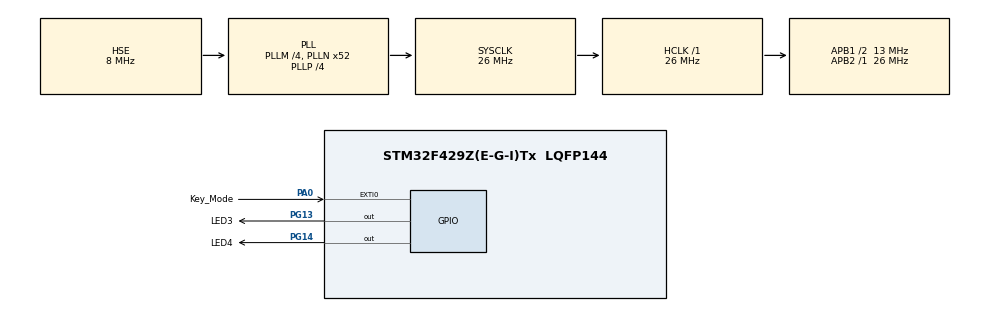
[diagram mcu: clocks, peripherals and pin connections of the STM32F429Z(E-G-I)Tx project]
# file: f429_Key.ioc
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Mcu.Family=STM32F4
Mcu.Name=STM32F429Z(E-G-I)Tx
Mcu.Package=LQFP144
NVIC.EXTI0_IRQn=true\:2\:0\:true\:false\:true
NVIC.PriorityGroup=NVIC_PRIORITYGROUP_2
NVIC.TIM2_IRQn=true\:3\:0\:true\:false\:true
PA0/WKUP.GPIO_Label=Key_Mode
PA0/WKUP.GPIO_ModeDefaultEXTI=GPIO_MODE_IT_RISING_FALLING
PA0/WKUP.Signal=GPXTI0
PG13.GPIO_Label=LED3
PG13.GPIO_Speed=GPIO_SPEED_FREQ_HIGH
PG13.Signal=GPIO_Output
PG14.GPIO_Label=LED4
PG14.GPIO_Speed=GPIO_SPEED_FREQ_HIGH
PG14.PinState=GPIO_PIN_SET
PG14.Signal=GPIO_Output
PH0/OSC_IN.Mode=HSE-External-Oscillator
PH0/OSC_IN.Signal=RCC_OSC_IN
PH1/OSC_OUT.Mode=HSE-External-Oscillator
PH1/OSC_OUT.Signal=RCC_OSC_OUT
ProjectManager.HeapSize=0x200
ProjectManager.StackSize=0x400
ProjectManager.TargetToolchain=MDK-ARM V5
RCC.48MHZClocksFreq_Value=26000000
RCC.AHBFreq_Value=26000000
RCC.APB1CLKDivider=RCC_HCLK_DIV2
RCC.APB1Freq_Value=13000000
RCC.APB1TimFreq_Value=26000000
RCC.APB2Freq_Value=26000000
RCC.APB2TimFreq_Value=26000000
RCC.CortexFreq_Value=26000000
RCC.HCLKFreq_Value=26000000
RCC.HSE_VALUE=8000000
RCC.HSI_VALUE=16000000
RCC.LSE_VALUE=32768
RCC.PLLM=4
RCC.PLLN=52
RCC.PLLP=RCC_PLLP_DIV4
RCC.PLLSourceVirtual=RCC_PLLSOURCE_HSE
RCC.SYSCLKFreq_VALUE=26000000
RCC.SYSCLKSource=RCC_SYSCLKSOURCE_PLLCLK
RCC.VCOOutputFreq_Value=104000000
TIM2.Period=9
TIM2.Prescaler=2599
TIM2.TIM_MasterOutputTrigger=TIM_TRGO_UPDATE
VP_TIM2_VS_ClockSourceINT.Mode=Internal
board=f429_Key

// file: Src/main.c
/**
  ******************************************************************************
  * File Name          : main.c
  * Description        : Main program body
  ******************************************************************************
  *
  * COPYRIGHT(c) 2016 STMicroelectronics
  *
  * Redistribution and use in source and binary forms, with or without modification,
  * are permitted provided that the following conditions are met:
  *   1. Redistributions of source code must retain the above copyright notice,
  *      this list of conditions and the following disclaimer.
  *   2. Redistributions in binary form must reproduce the above copyright notice,
  *      this list of conditions and the following disclaimer in the documentation
  *      and/or other materials provided with the distribution.
  *   3. Neither the name of STMicroelectronics nor the names of its contributors
  *      may be used to endorse or promote products derived from this software
  *      without specific prior written permission.
  *
  * THIS SOFTWARE IS PROVIDED BY THE COPYRIGHT HOLDERS AND CONTRIBUTORS "AS IS"
  * AND ANY EXPRESS OR IMPLIED WARRANTIES, INCLUDING, BUT NOT LIMITED TO, THE
  * IMPLIED WARRANTIES OF MERCHANTABILITY AND FITNESS FOR A PARTICULAR PURPOSE ARE
  * DISCLAIMED. IN NO EVENT SHALL THE COPYRIGHT HOLDER OR CONTRIBUTORS BE LIABLE
  * FOR ANY DIRECT, INDIRECT, INCIDENTAL, SPECIAL, EXEMPLARY, OR CONSEQUENTIAL
  * DAMAGES (INCLUDING, BUT NOT LIMITED TO, PROCUREMENT OF SUBSTITUTE GOODS OR
  * SERVICES; LOSS OF USE, DATA, OR PROFITS; OR BUSINESS INTERRUPTION) HOWEVER
  * CAUSED AND ON ANY THEORY OF LIABILITY, WHETHER IN CONTRACT, STRICT LIABILITY,
  * OR TORT (INCLUDING NEGLIGENCE OR OTHERWISE) ARISING IN ANY WAY OUT OF THE USE
  * OF THIS SOFTWARE, EVEN IF ADVISED OF THE POSSIBILITY OF SUCH DAMAGE.
  *
  ******************************************************************************
  */
#include "stm32f4xx_hal.h"

/* USER CODE BEGIN Includes */
#include "key.h"
/* USER CODE END Includes */

TIM_HandleTypeDef htim2;

/* USER CODE BEGIN PV */
/* Private variables ---------------------------------------------------------*/

/* USER CODE END PV */

void SystemClock_Config(void);
void Error_Handler(void);
static void MX_GPIO_Init(void);
static void MX_TIM2_Init(void);

/* USER CODE BEGIN PFP */
/* Private function prototypes -----------------------------------------------*/

/* USER CODE END PFP */

int main(void)
{

  /* USER CODE BEGIN 1 */
	KeyStatus Key_Value;
  /* USER CODE END 1 */

  /* MCU Configuration----------------------------------------------------------*/

  /* Reset of all peripherals, Initializes the Flash interface and the Systick. */
  HAL_Init();

  /* Configure the system clock */
  SystemClock_Config();

  /* Initialize all configured peripherals */
  MX_GPIO_Init();
  MX_TIM2_Init();

  /* USER CODE BEGIN 2 */
	//HAL_TIM_Base_Start_IT(&htim2);   // 开启定时器
  /* USER CODE END 2 */

  /* Infinite loop */
  while (1)
  {
		Key_Value = Key_Scan();
		if(Key_Value)
		{
			if(Key_Value == Key_Long)
			{
				HAL_GPIO_TogglePin(LED4_GPIO_Port, LED4_Pin);   // 添加 长按按键代码
			}

			if(Key_Value == Key_Short)
			{
				HAL_GPIO_TogglePin(LED3_GPIO_Port, LED3_Pin);		// 添加 短按按键代码
			}
		}
  /* USER CODE BEGIN 3 */
		;
  }
  /* USER CODE END 3 */

}

/** System Clock Configuration
*/
void SystemClock_Config(void)
{

  RCC_OscInitTypeDef RCC_OscInitStruct;
  RCC_ClkInitTypeDef RCC_ClkInitStruct;

  __HAL_RCC_PWR_CLK_ENABLE();

  __HAL_PWR_VOLTAGESCALING_CONFIG(PWR_REGULATOR_VOLTAGE_SCALE3);

  RCC_OscInitStruct.OscillatorType = RCC_OSCILLATORTYPE_HSE;
  RCC_OscInitStruct.HSEState = RCC_HSE_ON;
  RCC_OscInitStruct.PLL.PLLState = RCC_PLL_ON;
  RCC_OscInitStruct.PLL.PLLSource = RCC_PLLSOURCE_HSE;
  RCC_OscInitStruct.PLL.PLLM = 4;
  RCC_OscInitStruct.PLL.PLLN = 52;
  RCC_OscInitStruct.PLL.PLLP = RCC_PLLP_DIV4;
  RCC_OscInitStruct.PLL.PLLQ = 4;
  if (HAL_RCC_OscConfig(&RCC_OscInitStruct) != HAL_OK)
  {
    Error_Handler();
  }

  RCC_ClkInitStruct.ClockType = RCC_CLOCKTYPE_HCLK|RCC_CLOCKTYPE_SYSCLK
                              |RCC_CLOCKTYPE_PCLK1|RCC_CLOCKTYPE_PCLK2;
  RCC_ClkInitStruct.SYSCLKSource = RCC_SYSCLKSOURCE_PLLCLK;
  RCC_ClkInitStruct.AHBCLKDivider = RCC_SYSCLK_DIV1;
  RCC_ClkInitStruct.APB1CLKDivider = RCC_HCLK_DIV2;
  RCC_ClkInitStruct.APB2CLKDivider = RCC_HCLK_DIV1;
  if (HAL_RCC_ClockConfig(&RCC_ClkInitStruct, FLASH_LATENCY_0) != HAL_OK)
  {
    Error_Handler();
  }

  HAL_SYSTICK_Config(HAL_RCC_GetHCLKFreq()/1000);

  HAL_SYSTICK_CLKSourceConfig(SYSTICK_CLKSOURCE_HCLK);

  /* SysTick_IRQn interrupt configuration */
  HAL_NVIC_SetPriority(SysTick_IRQn, 0, 0);
}

/* TIM2 init function */
static void MX_TIM2_Init(void)
{

  TIM_ClockConfigTypeDef sClockSourceConfig;
  TIM_MasterConfigTypeDef sMasterConfig;

  htim2.Instance = TIM2;
  htim2.Init.Prescaler = 2599;
  htim2.Init.CounterMode = TIM_COUNTERMODE_UP;
  htim2.Init.Period = 9;
	//htim2.Init.Period = 4999;
  htim2.Init.ClockDivision = TIM_CLOCKDIVISION_DIV1;
  if (HAL_TIM_Base_Init(&htim2) != HAL_OK)
  {
    Error_Handler();
  }

  sClockSourceConfig.ClockSource = TIM_CLOCKSOURCE_INTERNAL;
  if (HAL_TIM_ConfigClockSource(&htim2, &sClockSourceConfig) != HAL_OK)
  {
    Error_Handler();
  }

  sMasterConfig.MasterOutputTrigger = TIM_TRGO_UPDATE;
  sMasterConfig.MasterSlaveMode = TIM_MASTERSLAVEMODE_DISABLE;
  if (HAL_TIMEx_MasterConfigSynchronization(&htim2, &sMasterConfig) != HAL_OK)
  {
    Error_Handler();
  }

}

/** Configure pins as
        * Analog
        * Input
        * Output
        * EVENT_OUT
        * EXTI
*/
static void MX_GPIO_Init(void)
{

  GPIO_InitTypeDef GPIO_InitStruct;

  /* GPIO Ports Clock Enable */
  __HAL_RCC_GPIOH_CLK_ENABLE();
  __HAL_RCC_GPIOA_CLK_ENABLE();
  __HAL_RCC_GPIOG_CLK_ENABLE();

  /*Configure GPIO pin : Key_Mode_Pin */
  GPIO_InitStruct.Pin = Key_Mode_Pin;
  GPIO_InitStruct.Mode = GPIO_MODE_IT_RISING;
  GPIO_InitStruct.Pull = GPIO_NOPULL;
  HAL_GPIO_Init(Key_Mode_GPIO_Port, &GPIO_InitStruct);

  /*Configure GPIO pins : LED3_Pin LED4_Pin */
  GPIO_InitStruct.Pin = LED3_Pin|LED4_Pin;
  GPIO_InitStruct.Mode = GPIO_MODE_OUTPUT_PP;
  GPIO_InitStruct.Pull = GPIO_NOPULL;
  GPIO_InitStruct.Speed = GPIO_SPEED_FREQ_HIGH;
  HAL_GPIO_Init(GPIOG, &GPIO_InitStruct);

  /*Configure GPIO pin Output Level */
  HAL_GPIO_WritePin(LED3_GPIO_Port, LED3_Pin, GPIO_PIN_RESET);

  /*Configure GPIO pin Output Level */
  HAL_GPIO_WritePin(LED4_GPIO_Port, LED4_Pin, GPIO_PIN_SET);

  /* EXTI interrupt init*/
  HAL_NVIC_SetPriority(EXTI0_IRQn, 2, 0);
  HAL_NVIC_EnableIRQ(EXTI0_IRQn);

}

void Error_Handler(void)
{
  while(1)
  {
  }
}

/************************ (C) COPYRIGHT STMicroelectronics *****END OF FILE****/
